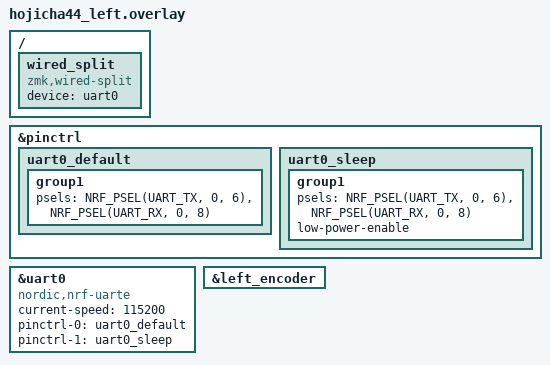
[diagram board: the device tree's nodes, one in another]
/*
 * Hojicha44 LEFT half overlay — DRAFT (see hojicha44.dtsi header).
 *
 * Split link: straight TRRS cable. Left TIP carries left-TX (D1 = P0.06),
 * left RING1 carries left-RX (D0 = P0.08). The far-end crossover is copper
 * (right half swaps at its MCU), so this UART map is the natural one.
 */
#include "hojicha44.dtsi"

&pinctrl {
    uart0_default: uart0_default {
        group1 {
            psels = <NRF_PSEL(UART_TX, 0, 6)>, <NRF_PSEL(UART_RX, 0, 8)>;
        };
    };
    uart0_sleep: uart0_sleep {
        group1 {
            psels = <NRF_PSEL(UART_TX, 0, 6)>, <NRF_PSEL(UART_RX, 0, 8)>;
            low-power-enable;
        };
    };
};

&uart0 {
    compatible = "nordic,nrf-uarte";
    status = "okay";
    current-speed = <115200>;
    pinctrl-0 = <&uart0_default>;
    pinctrl-1 = <&uart0_sleep>;
    pinctrl-names = "default", "sleep";
};

/ {
    wired_split {
        compatible = "zmk,wired-split";
        device = <&uart0>;
    };
};

&left_encoder {
    status = "okay";
};
